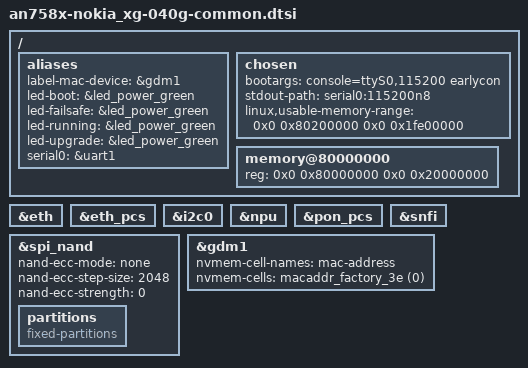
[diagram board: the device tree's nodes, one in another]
// SPDX-License-Identifier: GPL-2.0-only OR MIT

/ {
	aliases {
		label-mac-device = &gdm1;

		led-boot = &led_power_green;
		led-failsafe = &led_power_green;
		led-running = &led_power_green;
		led-upgrade = &led_power_green;

		serial0 = &uart1;
	};

	chosen {
		bootargs = "console=ttyS0,115200 earlycon";
		stdout-path = "serial0:115200n8";
		linux,usable-memory-range =
			<0x0 0x80200000 0x0 0x1fe00000>;
	};

	memory@80000000 {
		device_type = "memory";
		reg = <0x0 0x80000000 0x0 0x20000000>;
	};
};

&eth {
	status = "okay";
};

&eth_pcs {
	status = "okay";
};

&i2c0 {
	status = "okay";
};

&npu {
	status = "okay";
};

&pon_pcs {
	status = "okay";
};

&snfi {
	status = "okay";
};

&spi_nand {
	/*
	 *  ECC must be aligned with bootloader to prevent read errors.
	 *  Stock fw also uses NAND_ECC_NONE.
	 */
	nand-ecc-mode = "none";
	nand-ecc-step-size = <2048>;
	nand-ecc-strength = <0>;

	partitions: partitions {
		compatible = "fixed-partitions";
		#address-cells = <1>;
		#size-cells = <1>;
	};
};

&gdm1 {
	status = "okay";

	nvmem-cell-names = "mac-address";
	nvmem-cells = <&macaddr_factory_3e (0)>;
};
